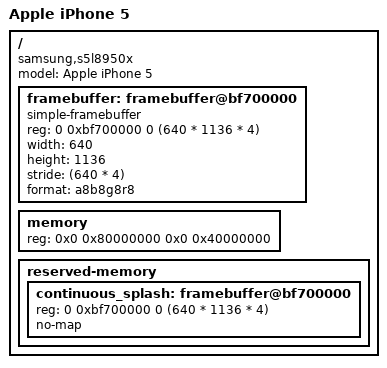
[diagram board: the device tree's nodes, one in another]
// SPDX-License-Identifier: BSD-3-Clause
/*
 * Samsung's Galaxy Xcover 3 Value Edition Device Tree
 *
 * Copyright (c) 2022, Ivaylo Ivanov <ivo.ivanov.ivanov1@gmail.com>
 */
/dts-v1/;

//#include "exynos3475.dtsi"
#include "skeleton.dtsi"

/ {
	model = "Apple iPhone 5";
	compatible = "samsung,s5l8950x", "samsung,s5l89xx";

	/* Some trees have it in a chosen {} */
	framebuffer: framebuffer@bf700000 {
		compatible = "simple-framebuffer";
		reg = <0 0xbf700000 0 (640 * 1136 * 4)>;
		width = <640>;
		height = <1136>;
		stride = <(640 * 4)>;
		format = "a8b8g8r8";
	};

	memory {
		device_type = "memory";

		reg = <0x0 0x80000000 0x0 0x40000000>;
	};

	reserved-memory {
		#address-cells = <1>;
		#size-cells = <1>;
		ranges;

		continuous_splash: framebuffer@bf700000 {
			reg = <0 0xbf700000 0 (640 * 1136 * 4)>;
			no-map;
		};
	};
};
